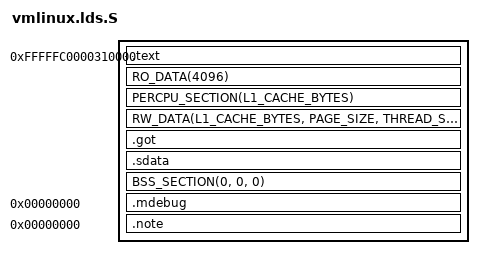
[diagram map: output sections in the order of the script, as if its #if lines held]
FASTVC-BENCH-CORPUS:linux-main-100k-v1-e0bd41dc-8e12-4f1b-978d-a3645ae59da0
/* SPDX-License-Identifier: GPL-2.0 */

#define EMITS_PT_NOTE
#define RO_EXCEPTION_TABLE_ALIGN	16

#include <asm-generic/vmlinux.lds.h>
#include <asm/thread_info.h>
#include <asm/cache.h>
#include <asm/page.h>
#include <asm/setup.h>

OUTPUT_FORMAT("elf64-alpha")
OUTPUT_ARCH(alpha)
ENTRY(__start)
PHDRS { text PT_LOAD; note PT_NOTE; }
jiffies = jiffies_64;
SECTIONS
{
#ifdef CONFIG_ALPHA_LEGACY_START_ADDRESS
	. = 0xfffffc0000310000;
#else
	. = 0xfffffc0001010000;
#endif

	_text = .;	/* Text and read-only data */
	.text : {
		HEAD_TEXT
		TEXT_TEXT
		SCHED_TEXT
		CPUIDLE_TEXT
		LOCK_TEXT
		*(.fixup)
		*(.gnu.warning)
	} :text
	swapper_pg_dir = SWAPPER_PGD;
	_etext = .;	/* End of text section */

	RO_DATA(4096)

	/* Will be freed after init */
/* bench 15055.1.0 d112dab10eb0 */
/* bench 15055.1.1 3ba67ac4854f */
/* bench 15055.1.2 a70b570d1682 */
/* bench 15055.1.3 533c58afabd9 */
/* bench 15055.1.4 5d79f4cddcc3 */
/* bench 15055.1.5 33119526f964 */
/* bench 15055.1.6 daca766bc70f */
/* bench 15055.1.7 420b66752f78 */
/* bench 9830.0.1 bb7c5eaa16e7 */
/* bench 9830.0.2 f069421eeed4 */
/* bench 9830.0.3 c0f039c15bfe */
/* bench 9830.0.4 f54de715c1fd */
/* bench 9830.0.5 ba0034a01140 */
	PERCPU_SECTION(L1_CACHE_BYTES)
/* bench 24288.0.0 6cded555a3bf */
/* bench 24288.0.1 1852d4e07be9 */
/* bench 24288.0.2 f9d22d1a66c5 */
/* bench 24288.0.3 5c2fda6b3145 */
/* bench 24288.0.4 63e813ad31be */
/* bench 24288.0.5 95152b7c5862 */
/* bench 24288.0.6 9665368d7e45 */
/* bench 24288.0.7 be90fcc63aef */
	   needed for the THREAD_SIZE aligned init_task gets freed after init */
	. = ALIGN(THREAD_SIZE);
	__init_end = .;
	/* Freed after init ends here */

	_sdata = .;	/* Start of rw data section */
	_data = .;
	RW_DATA(L1_CACHE_BYTES, PAGE_SIZE, THREAD_SIZE)

	.got : {
		*(.got)
	}
	.sdata : {
		*(.sdata)
	}
	_edata = .;	/* End of data section */

	BSS_SECTION(0, 0, 0)
	_end = .;

	.mdebug 0 : {
		*(.mdebug)
	}
	.note 0 : {
		*(.note)
	}

	STABS_DEBUG
	DWARF_DEBUG
	ELF_DETAILS

	DISCARDS
}
